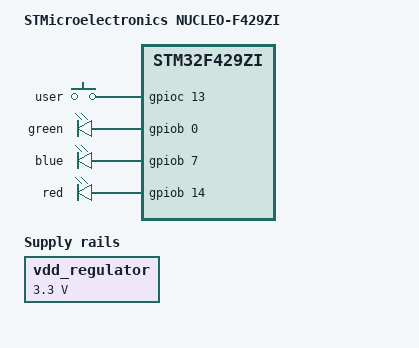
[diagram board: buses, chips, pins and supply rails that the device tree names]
/**
 * \file
 * \brief Devicetree for NUCLEO-F429ZI
 *
 * \author Copyright (C) 2017 Kamil Szczygiel http://www.distortec.com http://www.freddiechopin.info
 *
 * \par License
 * This Source Code Form is subject to the terms of the Mozilla Public License, v. 2.0. If a copy of the MPL was not
 * distributed with this file, You can obtain one at http://mozilla.org/MPL/2.0/.
 */

/dts-v1/;

#include "STM32F429ZI.dtsi"

/ {
	compatible = "ST,NUCLEO-F429ZI", "ST,STM32F429ZI";
	model = "STMicroelectronics NUCLEO-F429ZI";

	buttons {
		compatible = "gpio-keys";
		status = "okay";

		b1 {
			gpios = <&gpioc 13 0>;
			label = "user";
			status = "okay";
		};
	};

	leds {
		compatible = "gpio-leds";
		status = "okay";

		ld1 {
			gpios = <&gpiob 0 0>;
			label = "green";
			status = "okay";
		};

		ld2 {
			gpios = <&gpiob 7 0>;
			label = "blue";
			status = "okay";
		};

		ld3 {
			gpios = <&gpiob 14 0>;
			label = "red";
			status = "okay";
		};
	};

	regulators {
		#address-cells = <1>;
		#size-cells = <0>;

		vdd_regulator: regulator@0 {
			compatible = "regulator-fixed";
			reg = <0>;
			regulator-name = "VDD";
			regulator-min-microvolt = <3300000>;
			regulator-max-microvolt = <3300000>;
			regulator-always-on;
		};
	};
};

&clock_hse {
	ST,STM32-HSE-bypass;
	clock-frequency = <8000000>;
};

&gpiob {
	status = "okay";
};

&gpioc {
	status = "okay";
};
